# ble_rfcore_rfe_secure register map
Vendor: Texas Instruments
Peripheral module from a debugger description file (folder CC35X1E).
Registers are 32-bit, access per field, reset 0x0 unless marked. A register's access mark holds for its fields unless they carry their own. Offsets are as the file gives them; lines under a group give offsets from that group; [hi:lo] are bit positions; {n}, {i} and the like mark numbered series; 'fields as' and 'values as' point back to an identical list; <NAME> marks a mode.

## ble_rfcore_rfe_secure
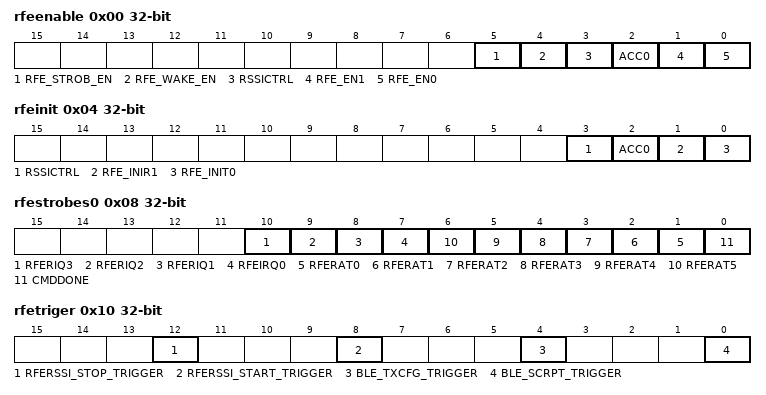
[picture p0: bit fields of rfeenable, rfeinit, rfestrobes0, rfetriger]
0x00 rfeenable — RF Engine Enable Register
  [5] RFE_STROB_EN rw — Enable RFE FW Strob Signal (not in use - signals are ORed)
  [4] RFE_WAKE_EN rw — Enable RFE to send Wake Events to MCE TOPsm
  [3] RSSICTRL rw — Enable for RSSI Control
  [2] ACC0 rw — Enables the Magnitude Accumulator 0
  [1] RFE_EN1 rw — RFE Enable 1
  [0] RFE_EN0 rw — RFE Enable 0
0x04 rfeinit — RF Engine Initialization Register
  [3] RSSICTRL wo — Synch reset for RSSI Control
  [2] ACC0 wo — Synch reset Magnitude Accumulator 0
  [1] RFE_INIR1 wo — Synch reset RFE1
  [0] RFE_INIT0 wo — Synch reset RFE0
0x08 rfestrobes0 — RF Engine (RFE) Strobe Register 0
  [10] RFERIQ3 wo — Firmware defined event for RFE IRQ3 Register type is WI ("Write Impulse"): Write generate 1-clock cycle pulse, Read 0.
  [9] RFERIQ2 wo — Firmware defined event for RFE IRQ1 Register type is WI ("Write Impulse"): Write generate 1-clock cycle pulse, Read 0.
  [8] RFERIQ1 wo — Firmware defined event for RFE IRQ1 Register type is WI ("Write Impulse"): Write generate 1-clock cycle pulse, Read 0.
  [7] RFEIRQ0 wo — Firmware defined event for RFE IRQ0 Register type is WI ("Write Impulse"): Write generate 1-clock cycle pulse, Read 0.
  [n+1] RFERAT{n} wo (n=0..5) — Firmware defined event for RFE RAT{n} Register type is WI ("Write Impulse"): Write generate 1-clock cycle pulse, Read 0.
  [0] CMDDONE wo — Signal command done to CPE
0x0C rfeeventmode — RF Engine (RFE) Event Mode Register
  [2:0] BLE_SCRPT_EVENT_MODE rw — BLE RFE to Scripter Event Mode
0x10 rfetriger — RF Engine (RFE) Trigger Register
  [12] RFERSSI_STOP_TRIGGER wo — RFE RSSI Stop Trigger - Stop the RSSI Accumulator operation.
  [8] RFERSSI_START_TRIGGER wo — RFE RSSI Start Trigger - Start the RSSI Accumulator operation.
  [4] BLE_TXCFG_TRIGGER wo — BLE RFE to TX-Config Trigger
  [0] BLE_SCRPT_TRIGGER wo — BLE RFE to Scripter Trigger
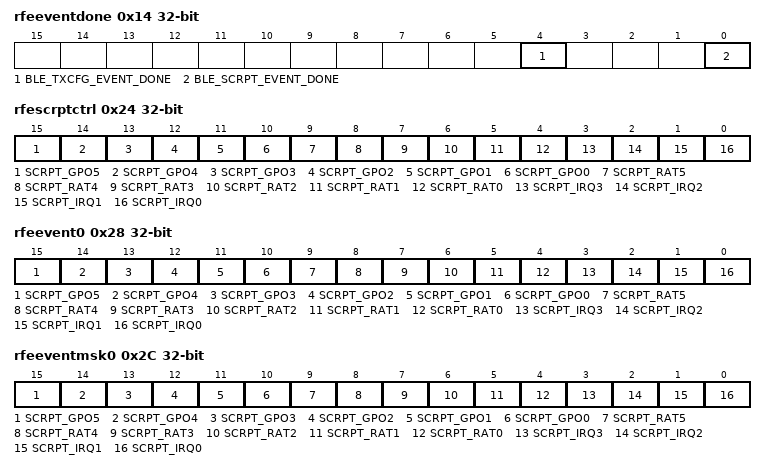
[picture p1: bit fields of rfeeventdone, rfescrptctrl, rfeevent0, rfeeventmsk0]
0x14 rfeeventdone — RF Engine (RFE) Event Done Register
  [4] BLE_TXCFG_EVENT_DONE rw — TX-Config Event is Done
  [0] BLE_SCRPT_EVENT_DONE rw — Scripter Event is Done
0x18 rfeeventmodedone — RF Engine (RFE) Event Mode Done Register
  [2:0] BLE_SCRPT_EVENT_MODE_DONE rw — BLE RFE to Scripter Event Mode Done
0x1C rfesync — RF Engine (RFE) SYNC Register
  [0] BLE_AGC_SYNC wo — BLE RFE Sync signal from the BLE Modem
0x20 rfeeof — RF Engine (RFE) EOF Register
  [0] BLE_AGC_EOF wo — BLE RFE - Rx Done Signal. Acts as End of Frame signal.
0x24 rfescrptctrl — RFE Direct GPO/IRQ/RAT Control by Phy-Scripter Register
  [15] SCRPT_GPO5 wo — Control GPO5 - Scripter TBD
  [14] SCRPT_GPO4 wo — Control GPO4 - Scripter TBD
  [13] SCRPT_GPO3 wo — Control GPO3 - Scripter Rx-OFF
  [12] SCRPT_GPO2 wo — Control GPO2 - Scripter Rx-ON
  [11] SCRPT_GPO1 wo — Control GPO1 - Scripter Tx-OFF
  [10] SCRPT_GPO0 wo — Control GPO0 - Scripter Tx-ON
  [9] SCRPT_RAT5 wo — Control RAT5 - Scripter TBD
  [8] SCRPT_RAT4 wo — Control RAT4 - Scripter TBD
  [7] SCRPT_RAT3 wo — Control RAT3 - Scripter Rx-OFF
  [6] SCRPT_RAT2 wo — Control RAT2 - Scripter Rx-ON
  [5] SCRPT_RAT1 wo — Control RAT1 - Scripter Tx-OFF
  [4] SCRPT_RAT0 wo — Control RAT0 - Scripter Tx-ON
  [3] SCRPT_IRQ3 wo — Control IRQ3 - Scripter Rx-OFF
  [2] SCRPT_IRQ2 wo — Control IRQ2 - Scripter Rx-ON
  [1] SCRPT_IRQ1 wo — Control IRQ1 - Scripter Tx-OFF
  [0] SCRPT_IRQ0 wo — Control IRQ0 - Scripter Tx-ON
0x28 rfeevent0 ro — RFE Event-0 Flag Register
  [15] SCRPT_GPO5 — Status GPO5 - Scripter TBD
  [14] SCRPT_GPO4 — Status GPO4 - Scripter TBD
  [13] SCRPT_GPO3 — Status GPO3 - Scripter Rx-OFF
  [12] SCRPT_GPO2 — Status GPO2 - Scripter Rx-ON
  [11] SCRPT_GPO1 — Status GPO1 - Scripter Tx-OFF
  [10] SCRPT_GPO0 — Status GPO0 - Scripter Tx-ON
  [9] SCRPT_RAT5 — Status RAT5 - Scripter TBD
  [8] SCRPT_RAT4 — Status RAT4 - Scripter TBD
  [7] SCRPT_RAT3 — Status RAT3 - Scripter Rx-OFF
  [6] SCRPT_RAT2 — Status RAT2 - Scripter Rx-ON
  [5] SCRPT_RAT1 — Status RAT1 - Scripter Tx-OFF
  [4] SCRPT_RAT0 — Status RAT0 - Scripter Tx-ON
  [3] SCRPT_IRQ3 — Status IRQ3 - Scripter Rx-OFF
  [2] SCRPT_IRQ2 — Status IRQ2 - Scripter Rx-ON
  [1] SCRPT_IRQ1 — Status IRQ1 - Scripter Tx-OFF
  [0] SCRPT_IRQ0 — Status IRQ0 - Scripter Tx-ON
0x2C rfeeventmsk0 — RFE Event-0 Mask Register
  [15] SCRPT_GPO5 rw — Enable mask for event RFEEVENT0. GPO5 - Scripter TBD
  [14] SCRPT_GPO4 rw — Enable mask for event RFEEVENT0. GPO4 - Scripter TBD
  [13] SCRPT_GPO3 rw — Enable mask for event RFEEVENT0. GPO3 - Scripter Rx-OFF
  [12] SCRPT_GPO2 rw — Enable mask for event RFEEVENT0. GPO2 - Scripter Rx-ON
  [11] SCRPT_GPO1 rw — Enable mask for event RFEEVENT0. GPO1 - Scripter Tx-OFF
  [10] SCRPT_GPO0 rw — Enable mask for event RFEEVENT0. GPO0 - Scripter Tx-ON
  [9] SCRPT_RAT5 rw — Enable mask for event RFEEVENT0. RAT5 - Scripter TBD
  [8] SCRPT_RAT4 rw — Enable mask for event RFEEVENT0. RAT4 - Scripter TBD
  [7] SCRPT_RAT3 rw — Enable mask for event RFEEVENT0. RAT3 - Scripter Rx-OFF
  [6] SCRPT_RAT2 rw — Enable mask for event RFEEVENT0. RAT2 - Scripter Rx-ON
  [5] SCRPT_RAT1 rw — Enable mask for event RFEEVENT0. RAT1 - Scripter Tx-OFF
  [4] SCRPT_RAT0 rw — Enable mask for event RFEEVENT0. RAT0 - Scripter Tx-ON
  [3] SCRPT_IRQ3 rw — Enable mask for event RFEEVENT0. IRQ3 - Scripter Rx-OFF
  [2] SCRPT_IRQ2 rw — Enable mask for event RFEEVENT0. IRQ2 - Scripter Rx-ON
  [1] SCRPT_IRQ1 rw — Enable mask for event RFEEVENT0. IRQ1 - Scripter Tx-OFF
  [0] SCRPT_IRQ0 rw — Enable mask for event RFEEVENT0. IRQ0 - Scripter Tx-ON
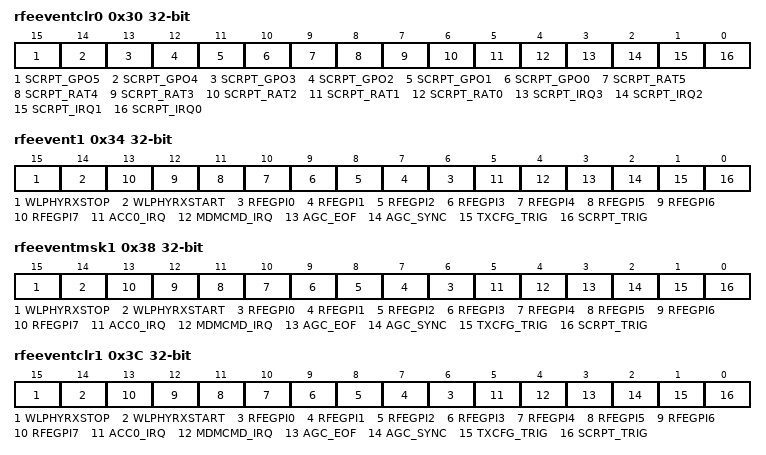
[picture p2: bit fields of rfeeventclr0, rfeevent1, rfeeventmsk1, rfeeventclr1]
0x30 rfeeventclr0 — RFE Event-0 Clear Register
  [15] SCRPT_GPO5 wo — Clear event RFEEVENT0. GPO5 - Scripter TBD
  [14] SCRPT_GPO4 wo — Clear event RFEEVENT0. GPO4 - Scripter TBD
  [13] SCRPT_GPO3 wo — Clear event RFEEVENT0. GPO3 - Scripter Rx-OFF
  [12] SCRPT_GPO2 wo — Clear event RFEEVENT0. GPO2 - Scripter Rx-ON
  [11] SCRPT_GPO1 wo — Clear event RFEEVENT0. GPO1 - Scripter Tx-OFF
  [10] SCRPT_GPO0 wo — Clear event RFEEVENT0. GPO0 - Scripter Tx-ON
  [9] SCRPT_RAT5 wo — Clear event RFEEVENT0. RAT5 - Scripter TBD
  [8] SCRPT_RAT4 wo — Clear event RFEEVENT0. RAT4 - Scripter TBD
  [7] SCRPT_RAT3 wo — Clear event RFEEVENT0. RAT3 - Scripter Rx-OFF
  [6] SCRPT_RAT2 wo — Clear event RFEEVENT0. RAT2 - Scripter Rx-ON
  [5] SCRPT_RAT1 wo — Clear event RFEEVENT0. RAT1 - Scripter Tx-OFF
  [4] SCRPT_RAT0 wo — Clear event RFEEVENT0. RAT0 - Scripter Tx-ON
  [3] SCRPT_IRQ3 wo — Clear event RFEEVENT0. IRQ3 - Scripter Rx-OFF
  [2] SCRPT_IRQ2 wo — Clear event RFEEVENT0. IRQ2 - Scripter Rx-ON
  [1] SCRPT_IRQ1 wo — Clear event RFEEVENT0. IRQ1 - Scripter Tx-OFF
  [0] SCRPT_IRQ0 wo — Clear event RFEEVENT0. IRQ0 - Scripter Tx-ON
0x34 rfeevent1 ro — RFE Event-1 Flag Register
  [15] WLPHYRXSTOP — Unused event line 15
  [14] WLPHYRXSTART — Unused event line 14
  [n+6] RFEGPI{n} (n=0..7) — External input event line RFC_GPI{n}
  [5] ACC0_IRQ — Accumulation period completed in magnitude accumulator 0
  [4] MDMCMD_IRQ — New command from MCE received in [MCERCEV.*] register
  [3] AGC_EOF — For Status Debug - RFEEOF.ble_agc_eof
  [2] AGC_SYNC — For Status of RFESYNC.ble_agc_sync
  [1] TXCFG_TRIG — For Status of RFETRIGER.ble_txcfg_trigger
  [0] SCRPT_TRIG — For Status of RFETRIGER.ble_scrpt_trigger
0x38 rfeeventmsk1 — RFE Event-1 Mask Register
  [15] WLPHYRXSTOP rw — Enable mask for event RFEEVENT1.WLPHYRXSTOP
  [14] WLPHYRXSTART rw — Enable mask for event RFEEVENT1.WLPHYRXSTART
  [n+6] RFEGPI{n} rw (n=0..7) — Enable mask for event RFEEVENT1.RFEGPI{n}
  [5] ACC0_IRQ rw — Enable mask for event RFEEVENT1.ACC0_IRQ
  [4] MDMCMD_IRQ rw — Enable mask for event RFEEVENT1.MDMCMD_IRQ
  [3] AGC_EOF rw — Enable mask for event RFEEVENT1.AGC_EOF
  [2] AGC_SYNC rw — Enable mask for event RFEEVENT1.AGC_SYNC
  [1] TXCFG_TRIG rw — Enable mask for event RFEEVENT1.TXCFG_TRIG
  [0] SCRPT_TRIG rw — Enable mask for event RFEEVENT1.SCRPT_TRIG
0x3C rfeeventclr1 — RFE Event-1 Clear Register
  [15] WLPHYRXSTOP wo — Clear event RFEEVENT1.WLPHYRXSTOP
  [14] WLPHYRXSTART wo — Clear event RFEEVENT1.WLPHYRXSTART
  [n+6] RFEGPI{n} wo (n=0..7) — Clear event RFEEVENT1.RFEGPI{n}
  [5] ACC0_IRQ wo — Clear event RFEEVENT1.ACC0_IRQ
  [4] MDMCMD_IRQ wo — Clear event RFEEVENT1.MDMCMD_IRQ
  [3] AGC_EOF wo — Clear event RFEEVENT1.AGC_EOF
  [2] AGC_SYNC wo — Clear event RFEEVENT1.AGC_SYNC
  [1] TXCFG_TRIG wo — Clear event RFEEVENT1.TXCFG_TRIG
  [0] SCRPT_TRIG wo — Clear event RFEEVENT1.SCRPT_TRIG
0x40 rfemcesend — RFE-to-MCE Send Command Register
  [15:0] RFECMD rw — Command to send to the MCE. Writing to this register will trigger an event in the MCE, and the command value written here will be readable in RFC_MDM:RFERCEV register.
0x44 rfemcercev ro — MCE-to-RFE Receive Command Register
  [15:0] MCECMD — Command received from MCE
{0x48+4i} rfespare{i} (i=0..5) — RFE Spare{i} Value
  [15:0] VAL rw — Spare register for use by firmware.
0x60 rfetrcsend — RFE Tracer Send Trigger Register
  [0] SEND wo — Sends a command to the tracer
0x64 rfetrcbusy ro — RFE Tracer Status Register
  [0] BUSY — Checks if the tracer is busy
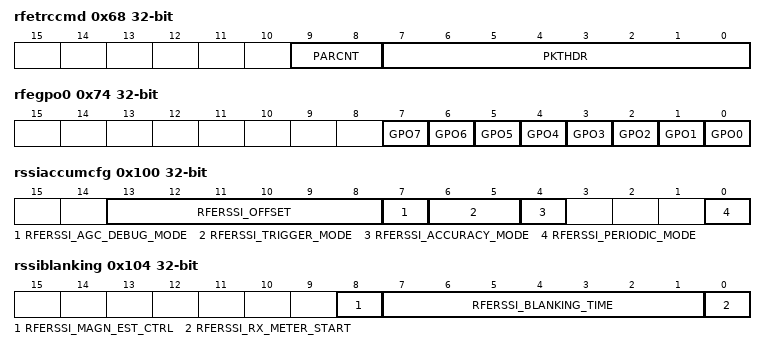
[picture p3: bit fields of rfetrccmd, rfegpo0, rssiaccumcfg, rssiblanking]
0x68 rfetrccmd — RFE Tracer Commmand Register
  [9:8] PARCNT rw — Number of parameters
  [7:0] PKTHDR rw — Packet header
0x6C rfetrcpar0 — RFE Tracer Command Parameter Register 0
  [15:0] PAR0 rw — Parameter 0
0x70 rfetrcpar1 — RFE Tracer Command Parameter Register 1
  [15:0] PAR1 rw — Parameter 1
0x74 rfegpo0 — RFE Direct GPO control register
  [n] GPO{n} rw (n=0..7) — Control GPO{n}
0x100 rssiaccumcfg — RSSI Offset Adjustment Register
  [13:8] RFERSSI_OFFSET rw — RSSI Offset to convert to dBm (unsigned). This is used by the RFE to adjust its RSSI calculations. RSSI offset can be given during the calculation.
  [7] RFERSSI_AGC_DEBUG_MODE rw — RSSI AGC Debug mode - Force AGC Value from RFESPARE0.val (for debug)
  [6:5] RFERSSI_TRIGGER_MODE rw — RSSI Operation mode select: 00: Default - Fine mode accuracy after SYNC Only. No Ext Trigger. 01: Trigger - By Ext-Trigger only, accuracy accordig to accuracy_mode register setting. 10: Both - By Ext-Trigger before SYNC use coarse accuracy, and As Default after SYNC. 00 : Default - Post-SYNC-Only: Fine mode accuracy after SYNC. 01 : Full - Pre-SYNC: Coars mode accuracy before SYNC. - Post-SYNC: Fine mode accuracy after SYNC. 10 : Trigger - By Ext Trigger only, accuracy accordig to accuracy_mode register. -The Trigger controlled by FW use next WI registers: - RFETRIGER.rferssi_start_trigger to Start Trigger. - RFETRIGER.rferssi_stop_trigger to Stop Trigger.
  [4] RFERSSI_ACCURACY_MODE rw — RSSI Accumulator Accurary mode: 0: fine 1: coarse
  [0] RFERSSI_PERIODIC_MODE rw — RSSI Accumulator - Enable periodic mode: 0: One-shot mode 1: Periodic mode
0x104 rssiblanking — BLE RSSI BLANKING Register
  [8] RFERSSI_MAGN_EST_CTRL rw — Control dynamicly the operation of the magnitude estimator engine - for power saving. (for furure use - not sure connected)
  [7:1] RFERSSI_BLANKING_TIME rw — Duration (of 8MHz cycles) in which we wait to start the RSSI accumulation.
  [0] RFERSSI_RX_METER_START rw — Status register indicate that "RxMeterStart" signal was received, so Ready for AGC Step and BLE Sync signals.
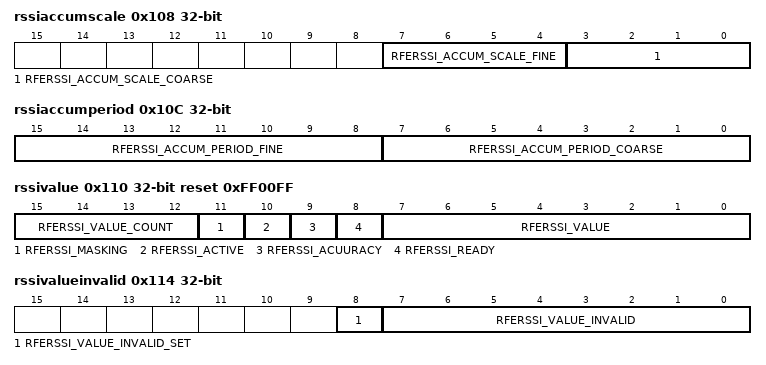
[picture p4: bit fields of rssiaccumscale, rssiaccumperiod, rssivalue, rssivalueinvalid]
0x108 rssiaccumscale — BLE RSSI ACCUMULATOR SCALE Register Set teh scaling value, by factor 1/2^(accum-scale) 0000 : DIV1 : 1/1 (no scaling) 0001 : DIV2 : 1/2 0010 : DIV4 : 1/4 0011 : DIV8 : 1/8 0100 : DIV16 : 1/16 0101 : DIV32 : 1/32 0110 : DIV64 : 1/64 0111 : DIV128 : 1/128 1XXX : DIV256 : 1/256
  [7:4] RFERSSI_ACCUM_SCALE_FINE rw — Fine Scaling value, by factor 1/2^Scale: Values are from 1 to 1/256.
  [3:0] RFERSSI_ACCUM_SCALE_COARSE rw — Coarse Scaling value, by factor 1/2^Scale: Values are from 1 to 1/256.
0x10C rssiaccumperiod — BLE RSSI ACCUMULATOR PERIOD Register Accumulation period, in incoming samples
  [15:8] RFERSSI_ACCUM_PERIOD_FINE rw — Fine Period value, in incoming samples. 0 means 1 sample. Range is from 1 to 256.
  [7:0] RFERSSI_ACCUM_PERIOD_COARSE rw — Coarse Period value, in incoming samples. 0 means 1 sample. Range is from 1 to 256.
0x110 rssivalue ro reset 0xFF00FF (reset mask 0xFFFF00FF) — BLE RSSI VALUE Register
  [15:12] RFERSSI_VALUE_COUNT — Counter as a stamp for any given valid RSSI calculation. (For FW use - to know if RSSI was updated - for periodic mode.)
  [11] RFERSSI_MASKING — RSSI is during masking so it is NOT working. (forced by AGC Step controled by wlphy-rx-ctrl).
  [10] RFERSSI_ACTIVE — Counter as a stamp of a given valid RSSI calculation for periodic mode. RSSI is during masking (force by AGC Step). RSSI is Active (during operation). RSSI Ready used accuracy_mode: '0' - fine, '1' - coarse.
  [9] RFERSSI_ACUURACY — Counter as a stamp of a given valid RSSI calculation for periodic mode. RSSI is during masking (force by AGC Step). RSSI is Active (during operation). RSSI Ready used accuracy_mode: '0' - fine, '1' - coarse.
  [8] RFERSSI_READY — RSSI Ready: 1: RSSI is ready to be read 0: Otherwise.
  [7:0] RFERSSI_VALUE — Calculated RSSI value (signed). If this register reads as -255 (0xFF) it means that the value is not yet valid.
0x114 rssivalueinvalid — BLE RSSI VALUE INVALID Register
  [8] RFERSSI_VALUE_INVALID_SET rw — Select the RFERSSI_VALUE_INVALID value with register in case of invalid value. Set to one when seeting the rferssi_value_invalid to specific value, Otherwise when RFERSSI_VALUE is not ready - HW will force it to 0x1FF.
  [7:0] RFERSSI_VALUE_INVALID rw — The value of BLE_RSSI_VALUE register in case of invalid value.
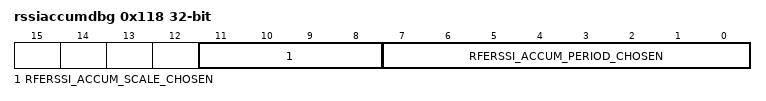
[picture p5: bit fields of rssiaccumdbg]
0x118 rssiaccumdbg ro — BLE RSSI ACCUMULATOR DEBUG Register
  [11:8] RFERSSI_ACCUM_SCALE_CHOSEN — Chosen RSSI accumulator Scale. Used for debug options.
  [7:0] RFERSSI_ACCUM_PERIOD_CHOSEN — Chosen RSSI accumulator Period. Used for debug options.
0x11C magnacc0 ro — Magnitude estimator 0 accumulator value
  [15:0] ACCVAL — Accumulated magnitude over the period
0x120 lin2logout ro reset 0x1E3C — Lin2Log output register
  [6:0] LOGVAL — Logarithmic output value. Calculation performed: LIN2LOGOUT = 20*log10(MATHACCELIN).
